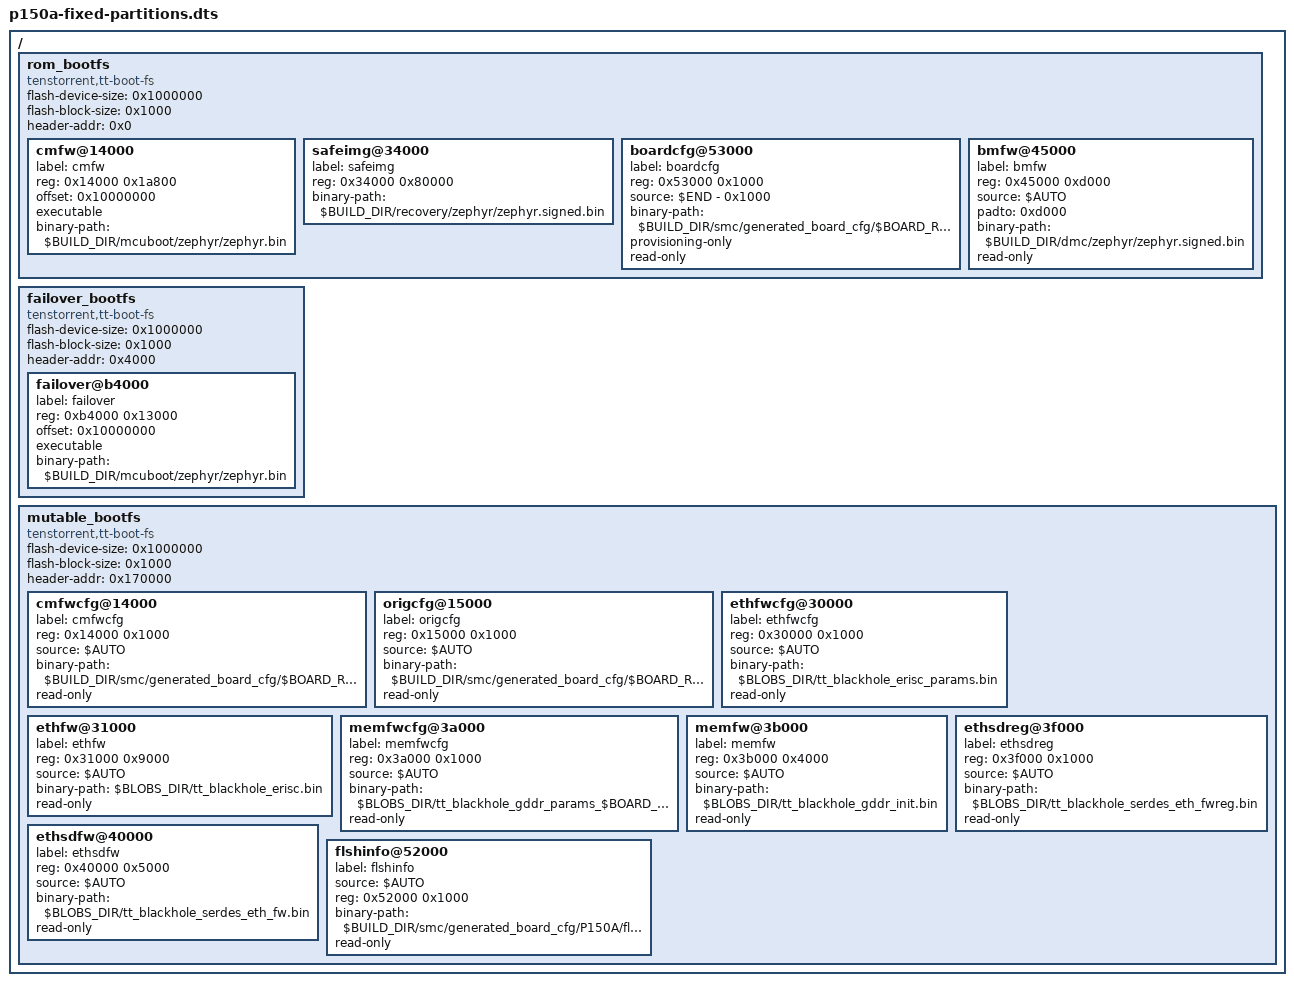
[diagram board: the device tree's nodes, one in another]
/*
 * Copyright (c) 2025 Tenstorrent AI ULC
 *
 * SPDX-License-Identifier: Apache-2.0
 */

/dts-v1/;

/ {
	rom_bootfs {
		compatible = "tenstorrent,tt-boot-fs", "fixed-partitions";
		#address-cells = <0x1>;
		#size-cells = <0x1>;
		flash-device-size = <0x1000000>;
		flash-block-size = <0x1000>;
		header-addr = <0x0>;

		cmfw@14000 {
			label = "cmfw";
			reg = <0x14000 0x1a800>;
			offset = <0x10000000>;
			executable;
			binary-path = "$BUILD_DIR/mcuboot/zephyr/zephyr.bin";
		};

		safeimg@34000 {
			label = "safeimg";
			reg = <0x34000 0x80000>;
			binary-path = "$BUILD_DIR/recovery/zephyr/zephyr.signed.bin";
		};

		boardcfg@53000 {
			label = "boardcfg";
			reg = <0x53000 0x1000>;
			source = "$END - 0x1000";
			binary-path = "$BUILD_DIR/smc/generated_board_cfg/$BOARD_REV/read_only.bin";
			provisioning-only;
			read-only;
		};

		bmfw@45000 {
			label = "bmfw";
			reg = <0x45000 0xd000>;
			source = "$AUTO";
			padto = <0xd000>;
			binary-path = "$BUILD_DIR/dmc/zephyr/zephyr.signed.bin";
			read-only;
		};
	};

	failover_bootfs {
		compatible = "tenstorrent,tt-boot-fs", "fixed-partitions";
		#address-cells = <0x1>;
		#size-cells = <0x1>;
		flash-device-size = <0x1000000>;
		flash-block-size = <0x1000>;
		header-addr = <0x4000>;

		failover@b4000 {
			label = "failover";
			reg = <0xb4000 0x13000>;
			offset = <0x10000000>;
			executable;
			binary-path = "$BUILD_DIR/mcuboot/zephyr/zephyr.bin";
		};
	};

	mutable_bootfs {
		compatible = "tenstorrent,tt-boot-fs", "fixed-partitions";
		#address-cells = <0x1>;
		#size-cells = <0x1>;
		flash-device-size = <0x1000000>;
		flash-block-size = <0x1000>;
		header-addr = <0x170000>;

		cmfwcfg@14000 {
			label = "cmfwcfg";
			reg = <0x14000 0x1000>;
			source = "$AUTO";
			binary-path = "$BUILD_DIR/smc/generated_board_cfg/$BOARD_REV/fw_table.bin";
			read-only;
		};

		origcfg@15000 {
			label = "origcfg";
			reg = <0x15000 0x1000>;
			source = "$AUTO";
			binary-path = "$BUILD_DIR/smc/generated_board_cfg/$BOARD_REV/fw_table.bin";
			read-only;
		};

		ethfwcfg@30000 {
			label = "ethfwcfg";
			reg = <0x30000 0x1000>;
			source = "$AUTO";
			binary-path = "$BLOBS_DIR/tt_blackhole_erisc_params.bin";
			read-only;
		};

		ethfw@31000 {
			label = "ethfw";
			reg = <0x31000 0x9000>;
			source = "$AUTO";
			binary-path = "$BLOBS_DIR/tt_blackhole_erisc.bin";
			read-only;
		};

		memfwcfg@3a000 {
			label = "memfwcfg";
			reg = <0x3a000 0x1000>;
			source = "$AUTO";
			binary-path = "$BLOBS_DIR/tt_blackhole_gddr_params_$BOARD_REV.bin";
			read-only;
		};

		memfw@3b000 {
			label = "memfw";
			reg = <0x3b000 0x4000>;
			source = "$AUTO";
			binary-path = "$BLOBS_DIR/tt_blackhole_gddr_init.bin";
			read-only;
		};

		ethsdreg@3f000 {
			label = "ethsdreg";
			reg = <0x3f000 0x1000>;
			source = "$AUTO";
			binary-path = "$BLOBS_DIR/tt_blackhole_serdes_eth_fwreg.bin";
			read-only;
		};

		ethsdfw@40000 {
			label = "ethsdfw";
			reg = <0x40000 0x5000>;
			source = "$AUTO";
			binary-path = "$BLOBS_DIR/tt_blackhole_serdes_eth_fw.bin";
			read-only;
		};

		flshinfo@52000 {
			label = "flshinfo";
			source = "$AUTO";
			reg = <0x52000 0x1000>;
			binary-path = "$BUILD_DIR/smc/generated_board_cfg/P150A/flash_info.bin";
			read-only;
		};
	};
};
